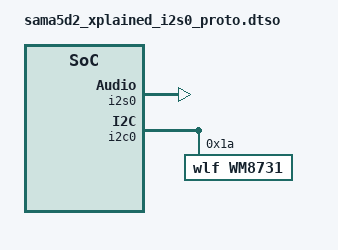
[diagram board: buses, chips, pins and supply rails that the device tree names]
// SPDX-License-Identifier: (GPL-2.0+ OR MIT)
/*
 * Device Tree file for SAMA5D2 Xplained board
 * overlay blob for I2S with PROTO board. The blob uses i2s0 and i2c0.
 *
 * Copyright (C) 2018 Microchip Technology, Inc.
 * Author: Codrin Ciubotariu <codrin.ciubotariu@microchip.com>
 *
 */
/dts-v1/;
/plugin/;

#include "sama5d2-pinfunc.h"

&i2s0 {
	status = "okay";
};

&i2c0 {
	#address-cells = <1>;
	#size-cells = <0>;
	wm8731: wm8731@1a {
		compatible = "wlf,wm8731";
		reg = <0x1a>;
	};
};

&{/} {
	sound {
		compatible = "mikroe,mikroe-proto";
		model = "wm8731 @ sama5d2_xplained";
		i2s-controller = <&i2s0>;
		audio-codec = <&wm8731>;
		dai-format = "i2s";
        };
};

&can0 {
	status = "disabled";
};
